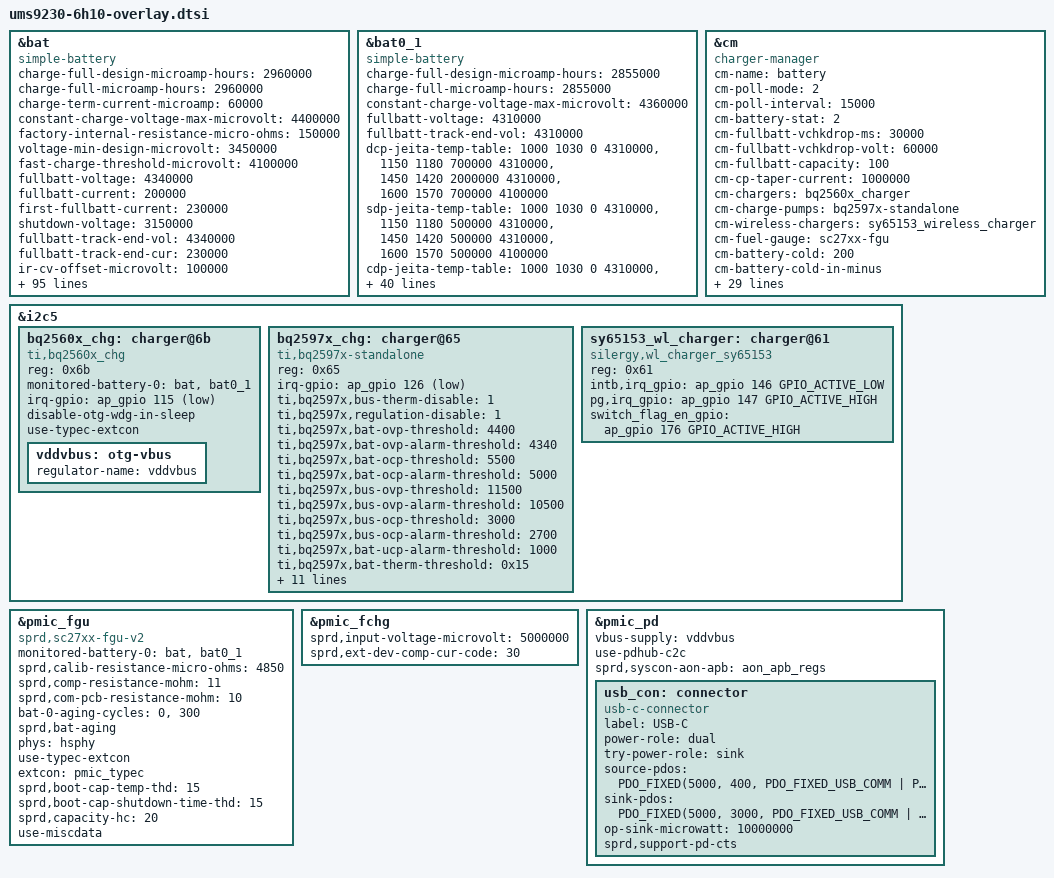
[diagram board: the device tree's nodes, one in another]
// SPDX-License-Identifier: GPL-2.0-only
/*
 * Unisoc Qogirl6 platform DTS file
 *
 * Copyright (C) 2020, Unisoc Inc.
 */

#include <dt-bindings/usb/pd.h>

&bat {
	compatible = "simple-battery";
	status = "okay";
	charge-full-design-microamp-hours = <2960000>;
	charge-full-microamp-hours = <2960000>;
	charge-term-current-microamp = <60000>;
	constant-charge-voltage-max-microvolt = <4400000>;
	factory-internal-resistance-micro-ohms = <150000>;
	voltage-min-design-microvolt = <3450000>;

	fast-charge-threshold-microvolt = <4100000>;
	fullbatt-voltage = <4340000>;
	fullbatt-current = <200000>;
	first-fullbatt-current = <230000>;
	shutdown-voltage = <3150000>;
	fullbatt-track-end-vol = <4340000>;
	fullbatt-track-end-cur = <230000>;


	ir-cv-offset-microvolt = <100000>;
	ir-rc-micro-ohms = <20000>;
	ir-us-upper-limit-microvolt = <4500000>;

	voltage-temp-table = <1110270 800>, <999440 850>, <890430 900>,
				<785590 950>, <687630 1000>, <598220 1050>,
				<517680 1100>, <446100 1150>, <383390 1200>,
				<328950 1250>, <281840 1300>, <241480 1350>,
				<207030 1400>, <177580 1450>, <152490 1500>,
				<131160 1550>, <113000 1600>, <97790 1650>;
	temp-advance-fullcap-table = <50 100>, <25 100>, <10 100>, <0 100>,
		<(-10) 100>, <(-20) 100>;

	charge-sdp-current-microamp = <500000 500000>;
	charge-dcp-current-microamp = <2000000 3000000>;
	charge-cdp-current-microamp = <1500000 1500000>;
	charge-unknown-current-microamp = <1000000 1000000>;
	charge-fchg-current-microamp = <3000000 2000000>;
	charge-flash-current-microamp = <4900000 2700000>;
	charge-wl-bpp-current-microamp = <1000000 1000000>;
	charge-wl-epp-current-microamp = <2000000 1000000>;

	cap-calib-energy-density-ocv-table = <3400000 3670000>, <3895000 4380000>;

	dcp-jeita-temp-table = <1000 1030 0 4340000>, <1150 1180 700000 4340000>,
		<1450 1420 2000000 4340000>, <1600 1570 700000 4100000>;
	sdp-jeita-temp-table = <1000 1030 0 4340000>, <1150 1180 500000 4340000>,
		<1450 1420 500000 4340000>, <1600 1570 500000 4100000>;
	cdp-jeita-temp-table = <1000 1030 0 4340000>, <1150 1180 700000 4340000>,
		<1450 1420 1500000 4340000>, <1600 1570 700000 4100000>;
	unknown-jeita-temp-table = <1000 1030 0 4340000>, <1150 1180 700000 4340000>,
		<1450 1420 1000000 4340000>, <1600 1570 700000 4100000>;
	fchg-jeita-temp-table = <1000 1030 0 4340000>, <1150 1180 700000 4340000>,
		<1450 1420 3250000 4340000>, <1600 1570 700000 4100000>;
	flash-jeita-temp-table = <1000 1030 0 4340000>, <1150 1180 1000000 4340000>,
		<1450 1420 5000000 4340000>, <1600 1570 1000000 4100000>;
	wl-bpp-jeita-temp-table = <1000 1030 0 4340000>, <1150 1180 500000 4340000>,
		<1450 1420 1000000 4340000>, <1600 1570 5000000 4100000>;
	wl-epp-jeita-temp-table = <1000 1030 0 4340000>, <1150 1180 500000 4340000>,
		<1450 1420 2000000 4340000>, <1600 1570 500000 4100000>;

	bat-temp = <(-20)>, <(-10)>, <0>, <10>, <25>, <45>;

	/* temp-fcc */
	temp-fcc-fcc = <2820000>, <2900000>, <2960000>, <2960000>, <2960000>, <2965000>;

	/* temp-hc */
	temp-hc-hc = <40>, <40>, <30>, <20>, <10>, <10>;

	/* temp-zero-point-voltage */
	temp-zpvol-zpvol = <3380000>, <3380000>, <3400000>, <3410000>, <3420000>, <3420000>;

	/* temp-abs-zero-point-voltage */
	temp-abs-zpvol-zpvol = <3370000>, <3370000>, <3390000>, <3400000>, <3410000>, <3410000>;

	/* temp-bat-voltage */
	temp-batvol-batvol = <3600000>, <3600000>, <3550000>, <3560000>, <3570000>, <3580000>;

	/* cap-temp-ocv */
	cap-temp-ocv-cap = <100>, <99>, <98>, <97>, <96>, <95>, <94>, <93>, <92>, <91>, <90>,
			<89>, <88>, <87>, <86>, <85>, <84>, <83>, <82>, <81>, <80>,
			<79>, <78>, <77>, <76>, <75>, <74>, <73>, <72>, <71>, <70>,
			<69>, <68>, <67>, <66>, <65>, <64>, <63>, <62>, <61>, <60>,
			<59>, <58>, <57>, <56>, <55>, <54>, <53>, <52>, <51>, <50>,
			<49>, <48>, <47>, <46>, <45>, <44>, <43>, <42>, <41>, <40>,
			<39>, <38>, <37>, <36>, <35>, <34>, <33>, <32>, <31>, <30>,
			<29>, <28>, <27>, <26>, <25>, <24>, <23>, <22>, <21>, <20>,
			<19>, <18>, <17>, <16>, <15>, <14>, <13>, <12>, <11>, <10>,
			<9>, <8>, <7>, <6>, <5>, <4>, <3>, <2>, <1>, <0>;
	cap-temp-ocv-ocv = <
			/* -20 celsius */
			4378000 4357000 4336000 4314000 4292000 4272000 4254000 4238000 4222000
			4206000 4190000 4176000 4165000 4153000 4142000 4130000 4118000 4104000
			4090000 4076000 4062000 4048000 4037000 4028000 4018000 4008000 3998000
			3989000 3980000 3972000 3963000 3954000 3946000 3938000 3930000 3922000
			3914000 3905000 3899000 3892000 3886000 3880000 3874000 3868000 3864000
			3860000 3856000 3851000 3847000 3844000 3840000 3838000 3834000 3830000
			3828000 3826000 3822000 3820000 3816000 3814000 3812000 3808000 3806000
			3804000 3801000 3798000 3796000 3793000 3790000 3788000 3784000 3782000
			3779000 3776000 3773000 3770000 3766000 3763000 3760000 3757000 3754000
			3750000 3746000 3742000 3739000 3736000 3734000 3732000 3728000 3724000
			3719000 3714000 3710000 3706000 3702000 3698000 3694000 3689000 3683000
			3674000 3660000
			/* -10 celsius */
			4380000 4364000 4346000 4330000 4313000 4296000 4282000 4267000 4253000
			4238000 4224000 4211000 4199000 4186000 4174000 4162000 4152000 4142000
			4132000 4122000 4112000 4100000 4086000 4074000 4061000 4048000 4036000
			4024000 4012000 4001000 3990000 3980000 3970000 3962000 3952000 3944000
			3935000 3926000 3918000 3909000 3900000 3892000 3886000 3878000 3872000
			3864000 3858000 3853000 3848000 3842000 3837000 3832000 3830000 3826000
			3822000 3820000 3816000 3814000 3812000 3810000 3807000 3804000 3802000
			3800000 3798000 3796000 3794000 3792000 3790000 3788000 3786000 3782000
			3780000 3776000 3774000 3771000 3768000 3764000 3760000 3756000 3752000
			3748000 3748000 3743000 3737000 3731000 3724000 3718000 3710000 3704000
			3700000 3696000 3694000 3691000 3688000 3682000 3670000 3646000 3607000
			3554000 3483000
			/* 0 celsius */
			4368000 4354000 4339000 4324000 4310000 4296000 4283000 4270000 4258000
			4245000 4232000 4220000 4210000 4198000 4186000 4175000 4164000 4154000
			4143000 4132000 4122000 4112000 4104000 4094000 4086000 4078000 4066000
			4052000 4040000 4026000 4014000 4004000 3995000 3986000 3977000 3968000
			3958000 3948000 3938000 3928000 3918000 3909000 3900000 3892000 3884000
			3875000 3868000 3862000 3856000 3849000 3843000 3838000 3833000 3828000
			3824000 3819000 3815000 3812000 3808000 3806000 3802000 3800000 3798000
			3796000 3794000 3792000 3791000 3790000 3788000 3786000 3784000 3782000
			3780000 3778000 3774000 3772000 3770000 3765000 3761000 3757000 3752000
			3748000 3743000 3737000 3731000 3724000 3717000 3710000 3702000 3698000
			3694000 3692000 3689000 3686000 3682000 3671000 3649000 3612000 3561000
			3494000 3400000
			/* 10 celsius */
			4371000 4359000 4347000 4334000 4322000 4310000 4299000 4287000 4276000
			4264000 4253000 4242000 4231000 4220000 4209000 4198000 4188000 4177000
			4167000 4157000 4146000 4136000 4126000 4116000 4106000 4096000 4088000
			4079000 4070000 4062000 4054000 4042000 4030000 4018000 4006000 3993000
			3984000 3976000 3967000 3958000 3950000 3940000 3929000 3918000 3908000
			3898000 3890000 3884000 3876000 3870000 3863000 3858000 3852000 3847000
			3842000 3837000 3832000 3828000 3824000 3820000 3815000 3812000 3808000
			3804000 3800000 3798000 3794000 3792000 3789000 3786000 3783000 3781000
			3779000 3776000 3774000 3772000 3768000 3764000 3760000 3756000 3752000
			3747000 3742000 3736000 3730000 3724000 3718000 3710000 3702000 3697000
			3694000 3692000 3692000 3690000 3686000 3678000 3658000 3620000 3568000
			3502000 3410000
			/* 25 celsius */
			4359000 4347000 4336000 4325000 4314000 4303000 4292000 4280000 4270000
			4260000 4248000 4238000 4226000 4216000 4206000 4194000 4184000 4174000
			4164000 4152000 4142000 4132000 4122000 4112000 4102000 4093000 4083000
			4074000 4066000 4058000 4050000 4039000 4027000 4016000 4006000 3998000
			3992000 3985000 3978000 3970000 3959000 3946000 3930000 3918000 3908000
			3900000 3892000 3886000 3880000 3874000 3868000 3862000 3858000 3852000
			3848000 3843000 3838000 3834000 3830000 3826000 3822000 3818000 3814000
			3811000 3808000 3804000 3802000 3798000 3795000 3792000 3788000 3784000
			3779000 3774000 3770000 3765000 3760000 3755000 3751000 3747000 3744000
			3740000 3735000 3729000 3722000 3718000 3712000 3704000 3696000 3693000
			3692000 3690000 3689000 3688000 3684000 3676000 3650000 3611000 3560000
			3492000 3400000
			/* 45 celsius */
			4362000 4352000 4341000 4331000 4321000 4310000 4300000 4289000 4278000
			4268000 4257000 4246000 4235000 4225000 4214000 4203000 4193000 4182000
			4172000 4162000 4151000 4141000 4131000 4121000 4111000 4101000 4092000
			4082000 4073000 4064000 4054000 4046000 4036000 4028000 4020000 4010000
			4002000 3994000 3986000 3978000 3970000 3959000 3947000 3934000 3922000
			3910000 3901000 3894000 3888000 3881000 3874000 3868000 3864000 3858000
			3854000 3848000 3844000 3839000 3834000 3830000 3826000 3822000 3818000
			3814000 3811000 3807000 3804000 3800000 3796000 3792000 3788000 3784000
			3778000 3772000 3766000 3760000 3754000 3750000 3746000 3742000 3736000
			3732000 3726000 3720000 3715000 3709000 3704000 3699000 3694000 3690000
			3686000 3682000 3676000 3670000 3664000 3659000 3652000 3596000 3531000
			3465000 3400000
			>;

	/* cap-temp-resist */
	cap-temp-resist-cap = <100>, <99>, <98>, <97>, <96>, <95>, <94>, <93>, <92>, <91>, <90>,
			<89>, <88>, <87>, <86>, <85>, <84>, <83>, <82>, <81>, <80>,
			<79>, <78>, <77>, <76>, <75>, <74>, <73>, <72>, <71>, <70>,
			<69>, <68>, <67>, <66>, <65>, <64>, <63>, <62>, <61>, <60>,
			<59>, <58>, <57>, <56>, <55>, <54>, <53>, <52>, <51>, <50>,
			<49>, <48>, <47>, <46>, <45>, <44>, <43>, <42>, <41>, <40>,
			<39>, <38>, <37>, <36>, <35>, <34>, <33>, <32>, <31>, <30>,
			<29>, <28>, <27>, <26>, <25>, <24>, <23>, <22>, <21>, <20>,
			<19>, <18>, <17>, <16>, <15>, <14>, <13>, <12>, <11>, <10>,
			<9>, <8>, <7>, <6>, <5>, <4>, <3>, <2>, <1>, <0>;
	cap-temp-resist-resist = <
		  /* -20 celsius m o */
		  1656 1656 1656 1656 1656 1656 1644 1626 1609 1592 1574
		  1558 1548 1536 1525 1514 1502 1486 1468 1452 1435 1418
		  1409 1402 1396 1390 1384 1379 1375 1372 1368 1364 1360
		  1358 1354 1352 1350 1347 1347 1348 1350 1351 1352 1356
		  1360 1366 1370 1376 1382 1388 1396 1404 1411 1419 1428
		  1438 1449 1459 1470 1480 1490 1501 1512 1522 1533 1546
		  1558 1571 1584 1596 1610 1624 1637 1650 1664 1678 1687
		  1694 1700 1706 1713 1721 1726 1730 1734 1738 1769 1770
		  1794 1821 1850 1884 1920 1956 1996 2037 2080 2131 2186
		  2246 2306
		  /* -10 celsius */
		  1022 1022 1022 1022 1022 1022 1017 1011 1006 1000 995
		  989  984  979  974  969  967  965  964  963  961  954
		  946  938  930  921  914  906  898  890  883  879  877
		  874  872  870  868  865  862  860  857  856  854  854
		  852  852  852  854  855  856  858  862  868  874  880
		  886  892  902  911  920  929  940  952  964  977  990
		  1002 1017 1032 1046 1060 1076 1082 1094 1099 1103 1107
		  1112 1116 1118 1123 1127 1133 1145 1148 1170 1195 1221
		  1247 1278 1309 1347 1386 1429 1476 1526 1574 1616 1657
		  1720 1796
		  /* 0 celsius */
		  586 586 586 586 586 586 586 584 583 582 581 579
		  577 575 573 571 570 569 568 566 566 568 572 576
		  579 582 578 570 564 556 548 548 549 550 551 552
		  548 544 538 534 529 525 521 518 514 510 508 508
		  508 508 506 508 508 510 510 512 515 519 524 528
		  532 538 547 556 564 573 584 596 608 620 634 646
		  650 663 666 669 672 675 680 688 692 692 696 694
		  704 740 740 762 784 811 842 876 916 960 1006 1059
		  1108 1161 1230 1320 1426
		  /* 10 celsius */
		  307 307 307 307 307 307 306 306 305 304 304 302
		  302 300 299 298 297 296 295 294 293 292 291 290
		  289 288 287 286 285 284 283 282 281 280 279 278
		  277 276 275 274 273 272 270 271 270 268 266 264
		  263 262 260 260 260 260 260 261 262 262 263 264
		  264 266 266 266 268 268 270 272 274 276 277 281
		  285 285 285 285 285 285 286 286 286 285 285 286
		  288 294 299 304 309 316 324 332 344 358 374 393
		  408 423 448 484 536
		  /* 25 celsius */
		  144 144 147 148 148 150 149 150 150 150 150 150
		  150 150 150 150 150 150 150 150 150 150 150 150
		  149 149 149 149 149 148 148 147 147 147 147 146
		  146 146 146 145 145 145 145 145 144 143 142 142
		  142 142 142 142 142 142 142 144 144 144 146 146
		  147 148 148 149 150 150 150 150 150 149 149 148
		  148 146 146 146 144 144 144 144 145 146 146 146
		  146 148 148 148 147 147 150 152 154 158 162 164
		  160 162 168 176 190
		  /* 45 celsius */
		  113 113 113 113 113 113 113 113 114 114 114 114
		  114 114 114 114 115 116 116 116 117 117 118 118
		  118 119 119 120 120 120 119 119 119 119 119 118
		  118 118 118 118 118 118 117 117 117 117 114 114
		  113 112 112 112 114 114 114 115 115 116 117 118
		  118 119 120 121 122 122 122 122 122 122 121 121
		  121 121 121 120 118 118 118 118 118 118 118 117
		  117 116 116 116 116 116 116 116 119 121 124 126
		  129 142 156 171 186
		>;
	cap-temp-resist-cycle = <300>, <600>;
	cap-temp-resist-ratio-0 = <
		  /* -20 celsius m o */
		  1030 1030 1030 1030 1030 1030 1030 1030 1030 1030 1040
		  1050 1050 1050 1060 1060 1060 1060 1060 1060 1060 1060
		  1060 1060 1060 1060 1060 1060 1060 1060 1060 1060 1060
		  1060 1060 1060 1060 1060 1060 1060 1060 1060 1060 1060
		  1060 1060 1060 1060 1060 1060 1060 1060 1060 1060 1060
		  1060 1060 1060 1060 1060 1060 1060 1060 1060 1050 1050
		  1050 1050 1050 1050 1050 1050 1050 1050 1050 1050 1050
		  1050 1050 1050 1050 1050 1050 1050 1050 1050 1050 1050
		  1050 1050 1050 1050 1050 1050 1050 1050 1050 1050 1050
		  1050 1050
		  /* -10 celsius */
		  1050 1050 1050 1050 1050 1050 1050 1050 1050 1050 1050
		  1050 1050 1050 1050 1050 1050 1050 1050 1050 1050 1050
		  1050 1050 1050 1050 1050 1050 1050 1050 1050 1050 1050
		  1050 1050 1050 1050 1050 1050 1050 1050 1050 1050 1050
		  1050 1050 1050 1050 1050 1050 1050 1050 1050 1050 1050
		  1050 1050 1050 1050 1050 1050 1050 1050 1050 1050 1050
		  1050 1050 1050 1050 1050 1050 1050 1050 1050 1050 1050
		  1050 1050 1050 1050 1050 1050 1050 1050 1050 1050 1050
		  1050 1050 1050 1050 1050 1050 1050 1050 1050 1050 1050
		  1050 1050
		  /* 0 celsius */
		  1160 1160 1160 1160 1160 1160 1160 1160 1170 1170 1170
		  1170 1170 1170 1170 1170 1170 1170 1170 1170 1170 1170
		  1170 1170 1170 1170 1170 1170 1170 1170 1170 1170 1170
		  1170 1170 1170 1180 1180 1180 1180 1180 1180 1180 1180
		  1180 1180 1190 1190 1190 1190 1190 1190 1190 1190 1190
		  1190 1190 1190 1190 1190 1190 1190 1190 1190 1190 1190
		  1190 1200 1200 1210 1220 1220 1220 1220 1220 1220 1230
		  1230 1230 1230 1230 1230 1230 1230 1230 1230 1230 1230
		  1230 1230 1230 1230 1250 1270 1290 1320 1350 1370 1400
		  1430 1430
		  /* 10 celsius */
		  1270 1270 1270 1270 1270 1270 1270 1270 1270 1280 1280
		  1280 1280 1290 1290 1290 1290 1290 1290 1290 1290 1290
		  1290 1300 1300 1300 1300 1300 1300 1300 1300 1300 1300
		  1300 1310 1310 1310 1310 1310 1310 1310 1310 1310 1310
		  1320 1320 1320 1320 1320 1320 1320 1320 1320 1320 1320
		  1320 1320 1330 1330 1330 1330 1330 1330 1330 1330 1330
		  1330 1330 1330 1330 1340 1340 1340 1340 1340 1340 1350
		  1360 1380 1400 1410 1430 1450 1470 1490 1500 1510 1520
		  1530 1530 1530 1530 1530 1530 1530 1530 1530 1530 1530
		  1530 1530
		  /* 25 celsius */
		  1110 1110 1110 1110 1110 1110 1110 1120 1120 1120 1130
		  1130 1140 1140 1140 1140 1140 1130 1130 1130 1130 1130
		  1130 1120 1120 1120 1120 1120 1120 1120 1120 1120 1120
		  1130 1130 1130 1130 1130 1140 1140 1140 1140 1140 1150
		  1150 1160 1160 1160 1160 1160 1160 1160 1160 1150 1150
		  1150 1150 1150 1160 1160 1160 1160 1160 1160 1150 1150
		  1150 1150 1150 1160 1160 1160 1160 1160 1160 1160 1160
		  1160 1160 1160 1160 1160 1160 1160 1160 1160 1150 1150
		  1150 1150 1150 1150 1150 1160 1160 1160 1160 1160 1160
		  1160 1160
		  /* 45 celsius */
		  1260 1260 1260 1260 1260 1260 1260 1270 1280 1290 1300
		  1300 1300 1300 1300 1300 1300 1300 1300 1300 1300 1300
		  1290 1290 1280 1270 1280 1290 1300 1310 1310 1310 1310
		  1310 1310 1310 1310 1310 1310 1310 1310 1310 1300 1290
		  1280 1270 1270 1270 1270 1270 1290 1290 1290 1290 1300
		  1310 1310 1310 1310 1310 1310 1310 1310 1300 1290 1290
		  1290 1290 1290 1300 1310 1310 1320 1320 1320 1320 1320
		  1320 1320 1320 1320 1320 1320 1320 1320 1320 1320 1310
		  1310 1310 1310 1310 1310 1310 1310 1320 1320 1320 1320
		  1320 1320
		>;

	cap-temp-resist-ratio-1 = <
		  /* -20 celsius m o */
		  1160 1160 1160 1160 1160 1160 1160 1160 1160 1170 1170
		  1180 1180 1190 1190 1190 1190 1200 1200 1210 1210 1210
		  1220 1220 1230 1230 1240 1250 1260 1270 1270 1270 1280
		  1290 1300 1310 1320 1340 1360 1380 1400 1400 1430 1460
		  1490 1520 1520 1520 1550 1590 1630 1660 1660 1690 1720
		  1750 1770 1770 1770 1770 1770 1770 1770 1770 1770 1770
		  1770 1770 1770 1770 1770 1770 1770 1770 1770 1770 1770
		  1770 1770 1770 1770 1770 1770 1770 1770 1770 1770 1770
		  1770 1770 1770 1770 1770 1770 1770 1770 1770 1770 1770
		  1770 1770
		  /* -10 celsius */
		  1180 1180 1180 1180 1180 1180 1180 1180 1170 1170 1170
		  1170 1170 1170 1170 1170 1170 1170 1170 1170 1170 1170
		  1170 1170 1170 1170 1170 1170 1170 1170 1170 1170 1170
		  1170 1170 1170 1170 1170 1170 1170 1170 1170 1170 1190
		  1190 1190 1190 1190 1200 1200 1200 1200 1200 1210 1210
		  1210 1210 1210 1210 1220 1240 1250 1270 1290 1290 1290
		  1290 1290 1290 1290 1300 1310 1320 1330 1340 1350 1350
		  1350 1370 1390 1410 1420 1440 1440 1460 1480 1500 1530
		  1550 1570 1590 1610 1620 1620 1620 1620 1620 1620 1620
		  1620 1620
		  /* 0 celsius */
		  1420 1420 1420 1420 1420 1420 1420 1420 1410 1410 1410
		  1410 1410 1410 1410 1410 1410 1410 1410 1410 1410 1410
		  1400 1400 1400 1400 1400 1400 1400 1400 1400 1400 1400
		  1400 1400 1400 1400 1400 1400 1400 1400 1400 1410 1410
		  1410 1410 1420 1420 1420 1420 1420 1420 1420 1420 1420
		  1420 1430 1430 1430 1430 1430 1430 1450 1450 1450 1450
		  1450 1450 1500 1500 1500 1500 1500 1500 1530 1530 1530
		  1530 1530 1530 1550 1550 1550 1550 1610 1610 1610 1610
		  1650 1700 1750 1800 1850 1900 1900 1900 1900 1900 1900
		  1900 1900
		  /* 10 celsius */
		  1400 1400 1400 1400 1400 1400 1400 1400 1400 1420 1420
		  1420 1420 1420 1420 1420 1420 1420 1420 1420 1420 1420
		  1420 1420 1420 1420 1420 1420 1410 1410 1410 1410 1410
		  1410 1410 1410 1410 1410 1410 1410 1410 1410 1410 1410
		  1410 1420 1420 1420 1420 1430 1430 1430 1430 1430 1420
		  1430 1430 1430 1430 1430 1430 1430 1430 1430 1430 1430
		  1430 1430 1430 1430 1470 1470 1470 1470 1470 1530 1530
		  1530 1530 1530 1590 1590 1590 1590 1630 1680 1710 1710
		  1780 1840 1900 1950 2000 2050 2100 2150 2200 2250 2250
		  2250 2250
		  /* 25 celsius */
		  1320 1320 1320 1320 1320 1320 1320 1320 1320 1320 1320
		  1320 1310 1310 1310 1310 1310 1310 1300 1300 1300 1300
		  1300 1290 1290 1290 1290 1290 1280 1280 1280 1280 1280
		  1280 1280 1280 1280 1280 1280 1280 1280 1280 1280 1290
		  1290 1300 1310 1310 1310 1310 1310 1310 1310 1310 1310
		  1310 1310 1310 1310 1310 1310 1310 1310 1310 1310 1310
		  1310 1310 1310 1310 1310 1310 1310 1320 1330 1340 1350
		  1350 1360 1360 1360 1360 1360 1370 1370 1370 1380 1390
		  1400 1410 1420 1430 1450 1460 1460 1460 1460 1460 1460
		  1460 1460
		  /* 45 celsius */
		  1298 1298 1298 1298 1298 1298 1298 1308 1318 1329 1339
		  1339 1339 1339 1339 1339 1339 1339 1339 1339 1339 1339
		  1329 1329 1318 1308 1318 1329 1339 1349 1349 1349 1349
		  1349 1349 1349 1349 1349 1349 1349 1349 1349 1339 1329
		  1318 1308 1308 1308 1308 1308 1329 1329 1329 1329 1339
		  1349 1349 1349 1349 1349 1349 1349 1349 1339 1329 1329
		  1329 1329 1329 1339 1349 1349 1360 1360 1360 1360 1360
		  1360 1360 1360 1360 1360 1360 1360 1360 1360 1360 1349
		  1349 1349 1349 1349 1349 1349 1349 1360 1360 1360 1360
		  1360 1360
		>;
};

&bat0_1 {
	compatible = "simple-battery";
	status = "okay";
	charge-full-design-microamp-hours = <2855000>;
	charge-full-microamp-hours = <2855000>;
	constant-charge-voltage-max-microvolt = <4360000>;

	fullbatt-voltage = <4310000>;

	fullbatt-track-end-vol = <4310000>;

	dcp-jeita-temp-table = <1000 1030 0 4310000>, <1150 1180 700000 4310000>,
		<1450 1420 2000000 4310000>, <1600 1570 700000 4100000>;
	sdp-jeita-temp-table = <1000 1030 0 4310000>, <1150 1180 500000 4310000>,
		<1450 1420 500000 4310000>, <1600 1570 500000 4100000>;
	cdp-jeita-temp-table = <1000 1030 0 4310000>, <1150 1180 700000 4310000>,
		<1450 1420 1500000 4310000>, <1600 1570 700000 4100000>;
	unknown-jeita-temp-table = <1000 1030 0 4310000>, <1150 1180 700000 4310000>,
		<1450 1420 1000000 4310000>, <1600 1570 700000 4100000>;
	fchg-jeita-temp-table = <1000 1030 0 4310000>, <1150 1180 700000 4310000>,
		<1450 1420 3250000 4310000>, <1600 1570 700000 4100000>;
	flash-jeita-temp-table = <1000 1030 0 4310000>, <1150 1180 1000000 4310000>,
		<1450 1420 5000000 4310000>, <1600 1570 1000000 4100000>;
	wl-bpp-jeita-temp-table = <1000 1030 0 4310000>, <1150 1180 500000 4310000>,
		<1450 1420 1000000 4310000>, <1600 1570 5000000 4100000>;
	wl-epp-jeita-temp-table = <1000 1030 0 4310000>, <1150 1180 500000 4310000>,
		<1450 1420 2000000 4310000>, <1600 1570 500000 4100000>;

	cap-calib-energy-density-ocv-table = <3400000 3660000>, <3910000 4480000>;

	bat-temp = <(-20)>, <(-10)>, <0>, <10>, <25>, <45>;

	/* temp-fcc */
	temp-fcc-fcc = <2767000>, <2789000>, <2820000>, <2845000>, <2855000>, <2850000>;

	/* cap-temp-ocv */
	cap-temp-ocv-cap = <100>, <99>, <98>, <97>, <96>, <95>, <94>, <93>, <92>, <91>, <90>,
		<89>, <88>, <87>, <86>, <85>, <84>, <83>, <82>, <81>, <80>,
		<79>, <78>, <77>, <76>, <75>, <74>, <73>, <72>, <71>, <70>,
		<69>, <68>, <67>, <66>, <65>, <64>, <63>, <62>, <61>, <60>,
		<59>, <58>, <57>, <56>, <55>, <54>, <53>, <52>, <51>, <50>,
		<49>, <48>, <47>, <46>, <45>, <44>, <43>, <42>, <41>, <40>,
		<39>, <38>, <37>, <36>, <35>, <34>, <33>, <32>, <31>, <30>,
		<29>, <28>, <27>, <26>, <25>, <24>, <23>, <22>, <21>, <20>,
		<19>, <18>, <17>, <16>, <15>, <14>, <13>, <12>, <11>, <10>,
		<9>, <8>, <7>, <6>, <5>, <4>, <3>, <2>, <1>, <0>;

	cap-temp-ocv-cycle-ocv = <
		/* -20 celsius */
		4338000 4318000 4296000 4276000 4258000 4242000 4226000 4210000 4196000 4180000
		4168000 4157000 4146000 4134000 4122000 4110000 4096000 4082000 4068000 4055000
		4042000 4032000 4023000 4014000 4004000 3994000 3986000 3977000 3968000 3960000
		3952000 3943000 3936000 3928000 3920000 3912000 3904000 3898000 3892000 3886000
		3880000 3873000 3868000 3864000 3860000 3856000 3851000 3847000 3844000 3840000
		3838000 3834000 3830000 3828000 3826000 3822000 3820000 3818000 3814000 3812000
		3810000 3807000 3804000 3802000 3800000 3796000 3794000 3792000 3788000 3786000
		3784000 3780000 3778000 3774000 3772000 3768000 3765000 3762000 3759000 3756000
		3752000 3748000 3745000 3742000 3738000 3735000 3734000 3731000 3727000 3723000
		3718000 3714000 3709000 3705000 3701000 3698000 3694000 3688000 3683000 3674000
		3660000
		/* -10 celsius */
		4340000 4324000 4308000 4292000 4278000 4263000 4249000 4235000 4221000 4209000
		4197000 4185000 4173000 4161000 4151000 4141000 4132000 4122000 4112000 4100000
		4088000 4076000 4063000 4050000 4038000 4027000 4016000 4004000 3992000 3982000
		3974000 3965000 3956000 3947000 3938000 3930000 3922000 3913000 3905000 3896000
		3890000 3882000 3876000 3868000 3862000 3856000 3852000 3846000 3841000 3836000
		3832000 3828000 3826000 3822000 3819000 3816000 3814000 3812000 3810000 3807000
		3805000 3802000 3800000 3798000 3796000 3794000 3792000 3790000 3788000 3786000
		3784000 3780000 3778000 3775000 3772000 3769000 3766000 3762000 3758000 3754000
		3750000 3748000 3746000 3740000 3735000 3729000 3722000 3716000 3709000 3704000
		3700000 3696000 3693000 3690000 3686000 3680000 3668000 3644000 3604000 3552000
		3483000
		/* 0 celsius */
		4328000 4314000 4300000 4287000 4274000 4262000 4250000 4238000 4226000 4215000
		4204000 4192000 4182000 4170000 4160000 4150000 4140000 4129000 4118000 4110000
		4102000 4094000 4084000 4076000 4064000 4052000 4039000 4026000 4014000 4004000
		3995000 3987000 3978000 3970000 3960000 3950000 3940000 3931000 3921000 3912000
		3904000 3895000 3886000 3878000 3870000 3864000 3858000 3853000 3847000 3841000
		3836000 3832000 3827000 3822000 3818000 3814000 3812000 3808000 3806000 3802000
		3800000 3798000 3796000 3794000 3792000 3791000 3790000 3788000 3786000 3784000
		3782000 3780000 3778000 3776000 3773000 3770000 3766000 3762000 3758000 3754000
		3750000 3746000 3740000 3734000 3728000 3721000 3714000 3707000 3701000 3696000
		3694000 3691000 3688000 3686000 3680000 3668000 3645000 3608000 3557000 3492000
		3400000
		/* 10 celsius */
		4332000 4319000 4308000 4296000 4286000 4274000 4264000 4252000 4242000 4231000
		4220000 4210000 4200000 4190000 4179000 4169000 4159000 4149000 4140000 4130000
		4120000 4110000 4101000 4092000 4084000 4076000 4067000 4059000 4050000 4038000
		4026000 4014000 4002000 3991000 3983000 3974000 3966000 3958000 3950000 3940000
		3930000 3919000 3909000 3899000 3892000 3884000 3878000 3872000 3865000 3859000
		3854000 3849000 3844000 3839000 3834000 3830000 3826000 3822000 3818000 3814000
		3810000 3806000 3804000 3800000 3796000 3794000 3791000 3789000 3786000 3784000
		3781000 3779000 3777000 3774000 3772000 3769000 3765000 3761000 3757000 3753000
		3749000 3744000 3738000 3732000 3726000 3721000 3714000 3706000 3700000 3696000
		3694000 3692000 3690000 3688000 3685000 3676000 3654000 3615000 3564000 3500000
		3410000
		/* 25 celsius */
		4319000 4308000 4298000 4287000 4277000 4266000 4256000 4245000 4234000 4224000
		4214000 4204000 4193000 4183000 4173000 4163000 4153000 4143000 4134000 4124000
		4114000 4105000 4095000 4086000 4077000 4068000 4061000 4054000 4044000 4032000
		4022000 4011000 4002000 3996000 3990000 3983000 3976000 3968000 3956000 3942000
		3928000 3916000 3907000 3899000 3892000 3886000 3880000 3874000 3869000 3864000
		3858000 3854000 3848000 3844000 3840000 3836000 3832000 3828000 3824000 3820000
		3817000 3813000 3810000 3807000 3804000 3801000 3798000 3794000 3791000 3788000
		3783000 3779000 3774000 3770000 3765000 3760000 3756000 3752000 3748000 3744000
		3741000 3736000 3731000 3725000 3720000 3714000 3708000 3700000 3694000 3692000
		3692000 3690000 3688000 3687000 3684000 3674000 3646000 3606000 3556000 3490000
		3400000
		/* 45 celsius */
		4322000 4312000 4302000 4291000 4281000 4271000 4260000 4250000 4240000 4230000
		4219000 4209000 4199000 4189000 4179000 4169000 4159000 4149000 4139000 4130000
		4120000 4110000 4101000 4092000 4082000 4074000 4064000 4056000 4048000 4038000
		4030000 4022000 4014000 4006000 3998000 3990000 3982000 3974000 3966000 3954000
		3942000 3931000 3920000 3908000 3899000 3893000 3887000 3880000 3874000 3868000
		3864000 3858000 3854000 3849000 3844000 3840000 3836000 3832000 3828000 3823000
		3820000 3816000 3813000 3809000 3806000 3802000 3798000 3795000 3791000 3787000
		3782000 3777000 3772000 3766000 3760000 3754000 3750000 3746000 3742000 3738000
		3733000 3728000 3722000 3717000 3711000 3706000 3701000 3697000 3692000 3688000
		3684000 3680000 3674000 3669000 3664000 3658000 3646000 3588000 3526000 3463000
		3400000
		>;
};

&cm {
	compatible = "charger-manager";
	status = "okay";
	cm-name = "battery";
	cm-poll-mode = <2>;
	cm-poll-interval = <15000>;
	cm-battery-stat = <2>;

	cm-fullbatt-vchkdrop-ms = <30000>;
	cm-fullbatt-vchkdrop-volt = <60000>;
	cm-fullbatt-capacity = <100>;
	/*Charge pump target charge current*/
	cm-cp-taper-current = <1000000>;

	cm-chargers = "bq2560x_charger";
	cm-charge-pumps = "bq2597x-standalone";
	cm-wireless-chargers = "sy65153_wireless_charger";
	cm-fuel-gauge = "sc27xx-fgu";

	/* in deci centigrade */
	cm-battery-cold = <200>;
	cm-battery-cold-in-minus;
	cm-battery-hot = <800>;
	cm-battery-temp-diff = <100>;

	/* Allow charging for 6hr */
	cm-charging-max = <21600000>;
	/* recovery charging after stop charging 45min */
	cm-discharging-max = <2700000>;

	/* the interval to feed charger watchdog */
	cm-wdt-interval = <60>;

	/* drop voltage in microVolts to allow shutdown */
	cm-shutdown-voltage = <3100000>;

	/* when 99% of the time is exceeded, it will be forced to 100% */
	cm-tickle-time-out = <1500>;

	/* how much time to allow capacity change */
	cm-one-cap-time = <30>;

	cm-thermal-zone = "board-thmzone";

	/* when the safe charging voltage is exceeded, stop charging */
	cm-charge-voltage-max = <6500000>;
	cm-fast-charge-voltage-max = <10500000>;
	cm-flash-charge-voltage-max = <12000000>;
	cm-wireless-charge-voltage-max = <6500000>;
	cm-wireless-fast-charge-voltage-max = <12000000>;
	/* drop voltage in microVolts to restart charging */
	cm-charge-voltage-drop = <700000>;
	cm-fast-charge-voltage-drop = <700000>;
	cm-flash-charge-voltage-drop = <1000000>;
	cm-wireless-charge-voltage-drop = <700000>;
	cm-wireless-fast-charge-voltage-drop = <1000000>;

	/* sprd_fchg parameter */
	sprd,support-fchg;
	sprd,support-pd-pps;
	sprd,pd-fixed-max-microwatt = <18000000>;

	monitored-battery-0 = <&bat &bat0_1>;
	cm-capacity-track;
	cm-keep-awake;

	phys = <&hsphy>;
	pd-extcon-enable;
	extcon = <&pmic_typec>, <&pmic_pd>;
	use-typec-extcon;
};

&i2c5 {
	#address-cells = <1>;
	#size-cells = <0>;

	status = "okay";
	bq2560x_chg: charger@6b {
		compatible = "ti,bq2560x_chg";
		reg = <0x6b>;
		monitored-battery-0 = <&bat &bat0_1>;
		irq-gpio = <&ap_gpio 115 GPIO_ACTIVE_LOW>;
		disable-otg-wdg-in-sleep;
		use-typec-extcon;
		vddvbus:otg-vbus {
			regulator-name = "vddvbus";
		};
	};

	bq2597x_chg: charger@65 {
		compatible = "ti,bq2597x-standalone";
		reg = <0x65>;
		irq-gpio = <&ap_gpio 126 GPIO_ACTIVE_LOW>;

		ti,bq2597x,bus-therm-disable = <1>;
		ti,bq2597x,regulation-disable = <1>;

		ti,bq2597x,bat-ovp-threshold = <4400>;
		ti,bq2597x,bat-ovp-alarm-threshold = <4340>;
		ti,bq2597x,bat-ocp-threshold = <5500>;
		ti,bq2597x,bat-ocp-alarm-threshold = <5000>;
		ti,bq2597x,bus-ovp-threshold = <11500>;
		ti,bq2597x,bus-ovp-alarm-threshold = <10500>;
		ti,bq2597x,bus-ocp-threshold = <3000>;
		ti,bq2597x,bus-ocp-alarm-threshold = <2700>;
		ti,bq2597x,bat-ucp-alarm-threshold = <1000>;
		ti,bq2597x,bat-therm-threshold = <0x15>;
		ti,bq2597x,bus-therm-threshold = <0x15>;
		ti,bq2597x,die-therm-threshold = <0xc8>;
		ti,bq2597x,ac-ovp-threshold = <13>;
		ti,bq2597x,sense-resistor-mohm = <5>;
		ti,bq2597x,adc-sample-bits = <13>;
		ti,bq2597x,ibat-regulation-threshold = <300>;
		ti,bq2597x,vbat-regulation-threshold = <100>;
		ti,bq2597x,vdrop-threshold = <400>;
		ti,bq2597x,vdrop-deglitch = <5000>;
		ti,bq2597x,ss-timeout = <100000>;
		ti,bq2597x,watchdog-timer = <30000>;
	};

	sy65153_wl_charger: charger@61 {
		compatible = "silergy,wl_charger_sy65153";
		reg = <0x61>;
		intb,irq_gpio = <&ap_gpio 146 GPIO_ACTIVE_LOW>;
		pg,irq_gpio = <&ap_gpio 147 GPIO_ACTIVE_HIGH>;
		/*switch_chg_en_gpio = <&ap_gpio 171 GPIO_ACTIVE_HIGH>;*/
		switch_flag_en_gpio = <&ap_gpio 176 GPIO_ACTIVE_HIGH>;
	};
};

&pmic_fgu {
	compatible = "sprd,sc27xx-fgu-v2", "sprd,sc2730-fgu-v2", "sprd,sprd-fgu";
	monitored-battery-0 = <&bat &bat0_1>;
/*	fgu-cap-remap-table = <1 2 3>, <2 3 2>, <98 99 2>, <99 100 3>; */
	sprd,calib-resistance-micro-ohms = <4850>;
	sprd,comp-resistance-mohm = <11>;
	sprd,com-pcb-resistance-mohm = <10>;
	bat-0-aging-cycles = <0>, <300>;
	sprd,bat-aging;

	phys = <&hsphy>;

	use-typec-extcon;
	extcon = <&pmic_typec>;

	sprd,boot-cap-temp-thd = <15>;
	sprd,boot-cap-shutdown-time-thd = <15>;

	sprd,capacity-hc = <20>;
	use-miscdata;
};

&pmic_fchg {
	status = "okay";
	sprd,input-voltage-microvolt = <5000000>;

	/* External device current compensation code value during sfcp handshaking */
	sprd,ext-dev-comp-cur-code = <30>;
};

&pmic_pd {
	status = "okay";
	vbus-supply = <&vddvbus>;
	use-pdhub-c2c;
	sprd,syscon-aon-apb = <&aon_apb_regs>;
	usb_con: connector {
		compatible = "usb-c-connector";
		label = "USB-C";
		power-role = "dual";
		try-power-role = "sink";
		source-pdos = <PDO_FIXED(5000, 400, PDO_FIXED_USB_COMM | PDO_FIXED_SUSPEND |
					 PDO_FIXED_DUAL_ROLE | PDO_FIXED_DATA_SWAP)>;
		sink-pdos = <PDO_FIXED(5000, 3000, PDO_FIXED_USB_COMM | PDO_FIXED_DUAL_ROLE |
				       PDO_FIXED_DATA_SWAP)
			     PDO_PPS_APDO(3300, 11000, 3000)>;
		op-sink-microwatt = <10000000>;

		sprd,support-pd-cts;
	};
};
